// Description : LIN description file created by PREEvision
// Created : 4/22/24, 5:05 PM

LIN_description_file;
LIN_protocol_version = "2.2";
LIN_language_version = "2.2";
LIN_speed = 19.2 kbps;

Nodes {
  Master: BCM, 10 ms, 0.01 ms;
  Slaves: MCL, WLML, DIAG_TESTER_LIN1;
}

Signals {
  CapoteSts: 3, 0, BCM, WLML;
  BatteryVoltageLevel: 7, 0, BCM, WLML;
  Fdbk_Pos_Ver_LH_Exmi: 8, 255, MCL, BCM;
  Fdbk_Pos_Hor_LH_Exmi: 8, 255, MCL, BCM;
  Mem_Pos_Hor_Exmi: 8, 255, BCM, MCL;
  Mem_Pos_Ver_Exmi: 8, 255, BCM, MCL;
  Mem_Exmi_Selected: 2, 3, BCM, MCL;
  Err_Watchdog_Timer_LH: 2, 3, MCL, BCM;
  Err_Heater_short_Open_Circuit_LH: 2, 3, MCL, BCM;
  Err_ElectroChrom_short_Open_Circuit_LH: 2, 3, MCL, BCM;
  Err_Potentiometer_V_Value_LH: 2, 3, MCL, BCM;
  Err_Glass_Actuator_LH: 2, 3, MCL, BCM;
  Err_Puddle_Light_LH: 2, 3, MCL, BCM;
  ERR_ST_EXMI_LH_06_LIN: 2, 3, MCL, BCM;
  ERR_ST_EXMI_LH_07_LIN: 2, 3, MCL, BCM;
  ERR_ST_EXMI_LH_08_LIN: 2, 3, MCL, BCM;
  Err_Fold_Short_Open_Circuit_LH: 2, 3, MCL, BCM;
  ERR_ST_EXMI_LH_10_LIN: 2, 3, MCL, BCM;
  Err_Undervoltage_LH: 2, 3, MCL, BCM;
  Err_Overvoltage_LH: 2, 3, MCL, BCM;
  Err_Heater_Undervoltage_LH: 2, 3, MCL, BCM;
  Err_Over_Temp_microC_LH: 2, 3, MCL, BCM;
  ERR_ST_EXMI_LH_15_LIN: 2, 3, MCL, BCM;
  VRS_EXMI_LH_LIN: 8, 255, MCL, BCM;
  ST_DSE_1_LH_WARN_LNCH_LIN: 4, 15, MCL, BCM;
  NOD_ERR_EXMI_LH_LIN: 2, 3, MCL, BCM;
  COMM_ERR_EXMI_LH_LIN: 1, 0, MCL, BCM;
  Mirror_Selected: 2, 2, BCM, MCL;
  Mirror_Movement_Direction_Cmd: 4, 15, BCM, MCL;
  Mirror_Fold_Cmd: 2, 3, BCM, MCL;
  Mirror_Electrochromic_Dimming_Cmd: 8, 255, BCM, MCL;
  Mirror_Heater_Cmd: 3, 7, BCM, MCL;
  Puddle_Light_Dimming_Cmd: 8, 255, BCM, MCL;
  Puddle_Light_LH_Mode_Cmd: 4, 15, BCM, MCL;
  Puddle_Light_RH_Mode_Cmd: 4, 15, BCM, MCL;
  WLMLShortDrop: 1, 0, BCM, WLML;
  WLMLShortLift: 1, 0, BCM, WLML;
  WLM_ComfortClosing: 1, 0, BCM, WLML;
  CmdIgnSts: 3, 0, BCM, WLML;
  WLMRShortDrop: 1, 0, BCM, DIAG_TESTER_LIN1, WLML;
  WLMRShortLift: 1, 0, BCM, DIAG_TESTER_LIN1, WLML;
  Key_off_enabler: 1, 0, BCM, WLML;
  WLML_Movement_Command: 3, 0, BCM, WLML;
  WLMR_Movement_Command: 3, 0, BCM, DIAG_TESTER_LIN1, WLML;
  WLML_Position_Command: 4, 11, BCM, WLML;
  WLMR_Position_Command: 4, 11, BCM, DIAG_TESTER_LIN1, WLML;
  WLM_CapoteWindowsMovementCmd: 2, 0, BCM, WLML;
  AntipinchEnabler: 2, 0, BCM, WLML;
  WindowSts_WLML: 4, 0, WLML, BCM;
  Position_Fbk_WLML: 4, 0, WLML, BCM;
  ShortDropMode_Sts_WLML: 1, 0, WLML, BCM;
  InitializationSts_WLML: 1, 0, WLML, BCM;
  AssemblyModeSts_WLML: 1, 0, WLML, BCM;
  ThermalSts_WLML: 2, 0, WLML, BCM;
  VoltageOutOfRange_WLML: 1, 0, WLML, BCM;
  ResponseError_WLML: 1, 0, WLML, BCM;
  CurrentFail_WLML: 1, 0, WLML, BCM;
  GenericFail_WLML: 1, 0, WLML, BCM;
  HallSensorFail_WLML: 1, 0, WLML, BCM;
  AntiPinchFail_WLML: 1, 0, WLML, BCM;
  RelayFail_WLML: 1, 0, WLML, BCM;
  PositionFail_WLML: 1, 0, WLML, BCM;
  ShortDropSignalFail_WLML: 1, 0, WLML, BCM;
  STS_LH_DoorStatus: 2, 0, BCM, WLML;
  ExternalTemperature: 9, 170, BCM, WLML;
  AnticlatterSts_WLML: 2, 0, WLML, BCM;
  VehicleSpeedFailSts: 1, 0, BCM, WLML;
  ExternalTemperatureFailSts: 1, 0, BCM, WLML;
  VehicleSpeed: 13, 0, BCM, WLML;
}

Frames {
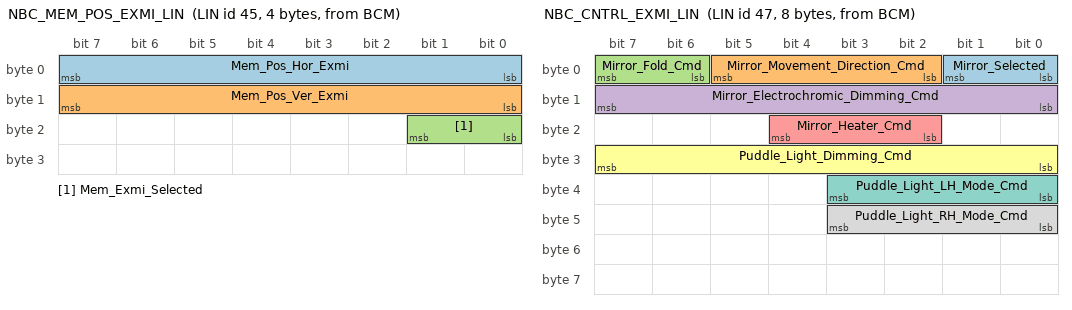
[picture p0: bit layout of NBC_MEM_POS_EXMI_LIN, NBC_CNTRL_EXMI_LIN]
  NBC_MEM_POS_EXMI_LIN: 45, BCM, 4 {
    Mem_Pos_Hor_Exmi, 0;
    Mem_Pos_Ver_Exmi, 8;
    Mem_Exmi_Selected, 16;
  }
  Fdbk_Pos_Exmi_LH: 17, MCL, 2 {
    Fdbk_Pos_Hor_LH_Exmi, 0;
    Fdbk_Pos_Ver_LH_Exmi, 8;
  }
  NBC_CNTRL_EXMI_LIN: 47, BCM, 8 {
    Mirror_Selected, 0;
    Mirror_Movement_Direction_Cmd, 2;
    Mirror_Fold_Cmd, 6;
    Mirror_Electrochromic_Dimming_Cmd, 8;
    Mirror_Heater_Cmd, 18;
    Puddle_Light_Dimming_Cmd, 24;
    Puddle_Light_LH_Mode_Cmd, 32;
    Puddle_Light_RH_Mode_Cmd, 40;
  }
  Err_LH_Exmi_Sts: 15, MCL, 8 {
    Err_Watchdog_Timer_LH, 0;
    Err_Heater_short_Open_Circuit_LH, 2;
    Err_ElectroChrom_short_Open_Circuit_LH, 4;
    Err_Potentiometer_V_Value_LH, 6;
    Err_Glass_Actuator_LH, 8;
    Err_Puddle_Light_LH, 10;
    ERR_ST_EXMI_LH_06_LIN, 12;
    ERR_ST_EXMI_LH_07_LIN, 14;
    ERR_ST_EXMI_LH_08_LIN, 16;
    Err_Fold_Short_Open_Circuit_LH, 18;
    ERR_ST_EXMI_LH_10_LIN, 20;
    Err_Undervoltage_LH, 22;
    Err_Overvoltage_LH, 24;
    Err_Heater_Undervoltage_LH, 26;
    Err_Over_Temp_microC_LH, 28;
    ERR_ST_EXMI_LH_15_LIN, 30;
    VRS_EXMI_LH_LIN, 32;
  }
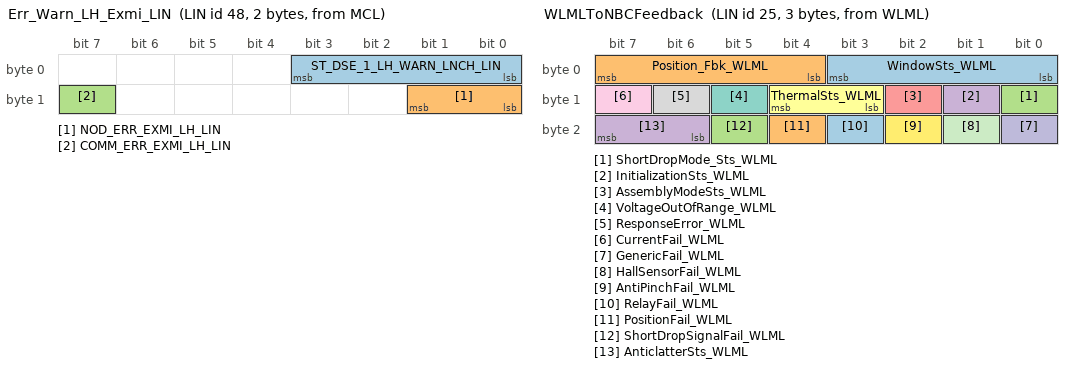
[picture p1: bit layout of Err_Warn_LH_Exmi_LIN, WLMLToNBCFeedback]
  Err_Warn_LH_Exmi_LIN: 48, MCL, 2 {
    ST_DSE_1_LH_WARN_LNCH_LIN, 0;
    NOD_ERR_EXMI_LH_LIN, 8;
    COMM_ERR_EXMI_LH_LIN, 15;
  }
  NBCToWLMCommand: 24, BCM, 8 {
    WLMLShortDrop, 7;
    WLMLShortLift, 8;
    WLM_ComfortClosing, 9;
    CmdIgnSts, 20;
    WLMRShortDrop, 23;
    WLMRShortLift, 24;
    Key_off_enabler, 25;
    WLML_Movement_Command, 26;
    WLMR_Movement_Command, 29;
    WLML_Position_Command, 46;
    WLMR_Position_Command, 50;
    WLM_CapoteWindowsMovementCmd, 54;
    AntipinchEnabler, 56;
    ExternalTemperature, 10;
    BatteryVoltageLevel, 0;
    STS_LH_DoorStatus, 61;
    CapoteSts, 58;
    ExternalTemperatureFailSts, 19;
    VehicleSpeedFailSts, 45;
    VehicleSpeed, 32;
  }
  WLMLToNBCFeedback: 25, WLML, 3 {
    WindowSts_WLML, 0;
    Position_Fbk_WLML, 4;
    ShortDropMode_Sts_WLML, 8;
    InitializationSts_WLML, 9;
    AssemblyModeSts_WLML, 10;
    ThermalSts_WLML, 11;
    VoltageOutOfRange_WLML, 13;
    ResponseError_WLML, 14;
    CurrentFail_WLML, 15;
    GenericFail_WLML, 16;
    HallSensorFail_WLML, 17;
    AntiPinchFail_WLML, 18;
    RelayFail_WLML, 19;
    PositionFail_WLML, 20;
    ShortDropSignalFail_WLML, 21;
    AnticlatterSts_WLML, 22;
  }
}

Node_attributes {
  MCL {
    LIN_protocol = "1.3";
    configured_NAD = 0x3;
  }
  WLML {
    LIN_protocol = "2.2";
    configured_NAD = 0x71;
    initial_NAD = 0x71;
    product_id = 0x0000, 0x0000, 0x00;
    response_error = ResponseError_WLML;
    P2_min = 50 ms;
    configurable_frames {
      NBCToWLMCommand;
      WLMLToNBCFeedback;
    }
  }
  DIAG_TESTER_LIN1 {
    LIN_protocol = "1.3";
    configured_NAD = 0x40;
  }
}

Schedule_tables {
  Init {
    SlaveResp delay 10 ms;
    MasterReq delay 10 ms;
  }
  MCL {
    NBC_MEM_POS_EXMI_LIN delay 10 ms;
    Fdbk_Pos_Exmi_LH delay 10 ms;
    Err_LH_Exmi_Sts delay 10 ms;
    NBC_CNTRL_EXMI_LIN delay 10 ms;
    Err_Warn_LH_Exmi_LIN delay 10 ms;
  }
  WLML_MCL {
    NBC_MEM_POS_EXMI_LIN delay 10 ms;
    Fdbk_Pos_Exmi_LH delay 10 ms;
    Err_LH_Exmi_Sts delay 10 ms;
    NBCToWLMCommand delay 10 ms;
    NBC_CNTRL_EXMI_LIN delay 10 ms;
    Err_Warn_LH_Exmi_LIN delay 10 ms;
    WLMLToNBCFeedback delay 10 ms;
  }
  WLML {
    NBCToWLMCommand delay 10 ms;
    WLMLToNBCFeedback delay 10 ms;
  }
}

Signal_encoding_types {
  Mem_Pos_Hor_Exmi_Encoding {
    logical_value, 255, "Invalid Signal";
    physical_value, 0, 255, 1, 0, "Position Value";
  }
  Mem_Pos_Ver_Exmi_Encoding {
    logical_value, 255, "Invalid Signal";
    physical_value, 0, 255, 1, 0, "Position Value";
  }
  Mem_Exmi_Selected_Encoding {
    logical_value, 0, "Left Mirror";
    logical_value, 1, "Right Mirror";
    logical_value, 2, "Not Used";
    logical_value, 3, "Invalid Signal";
  }
  Err_Watchdog_Timer_LH_Encoding {
    logical_value, 0, "No Failure";
    logical_value, 1, "Failure Active";
    logical_value, 2, "Not used";
    logical_value, 3, "Invalid Signal";
  }
  Err_Heater_short_Open_Circuit_LH_Encoding {
    logical_value, 0, "No Failure";
    logical_value, 1, "Failure Active";
    logical_value, 2, "Not used";
    logical_value, 3, "Invalid Signal";
  }
  Err_ElectroChrom_short_Open_Circuit_LH_Encoding {
    logical_value, 0, "No Failure";
    logical_value, 1, "Failure Active";
    logical_value, 2, "Not used";
    logical_value, 3, "Invalid Signal";
  }
  Err_Potentiometer_V_Value_LH_Encoding {
    logical_value, 0, "No Failure";
    logical_value, 1, "Failure Active";
    logical_value, 2, "Not used";
    logical_value, 3, "Invalid Signal";
  }
  Err_Glass_Actuator_LH_Encoding {
    logical_value, 0, "No Failure";
    logical_value, 1, "Failure Active";
    logical_value, 2, "Not used";
    logical_value, 3, "Invalid Signal";
  }
  Err_Puddle_Light_LH_Encoding {
    logical_value, 0, "No Failure";
    logical_value, 1, "Failure Active";
    logical_value, 2, "Not used";
    logical_value, 3, "Invalid Signal";
  }
  ERR_ST_EXMI_LH_06_LIN_Encoding {
    logical_value, 0, "No Failure";
    logical_value, 1, "Failure Active";
    logical_value, 2, "Not used";
    logical_value, 3, "Invalid Signal";
  }
  ERR_ST_EXMI_LH_07_LIN_Encoding {
    logical_value, 0, "No Failure";
    logical_value, 1, "Failure Active";
    logical_value, 2, "Not used";
    logical_value, 3, "Invalid Signal";
  }
  ERR_ST_EXMI_LH_08_LIN_Encoding {
    logical_value, 0, "No Failure";
    logical_value, 1, "Failure Active";
    logical_value, 2, "Not used";
    logical_value, 3, "Invalid Signal";
  }
  Err_Fold_Short_Open_Circuit_LH_Encoding {
    logical_value, 0, "No Failure";
    logical_value, 1, "Failure Active";
    logical_value, 2, "Not used";
    logical_value, 3, "Invalid Signal";
  }
  ERR_ST_EXMI_LH_10_LIN_Encoding {
    logical_value, 0, "No Failure";
    logical_value, 1, "Failure Active";
    logical_value, 2, "Not used";
    logical_value, 3, "Invalid Signal";
  }
  Err_Undervoltage_LH_Encoding {
    logical_value, 0, "No Failure";
    logical_value, 1, "Failure Active (<8,5V)";
    logical_value, 2, "Not used";
    logical_value, 3, "Invalid Signal";
  }
  Err_Overvoltage_LH_Encoding {
    logical_value, 0, "No Failure";
    logical_value, 1, "Failure Active (>16,5V)";
    logical_value, 2, "Not used";
    logical_value, 3, "Invalid Signal";
  }
  Err_Heater_Undervoltage_LH_Encoding {
    logical_value, 0, "No Failure";
    logical_value, 1, "Failure Active";
    logical_value, 2, "Not used";
    logical_value, 3, "Invalid Signal";
  }
  Err_Over_Temp_microC_LH_Encoding {
    logical_value, 0, "No Failure";
    logical_value, 1, "Failure Active";
    logical_value, 2, "Not used";
    logical_value, 3, "Invalid Signal";
  }
  ERR_ST_EXMI_LH_15_LIN_Encoding {
    logical_value, 0, "No Failure";
    logical_value, 1, "Failure Active";
    logical_value, 2, "Not used";
    logical_value, 3, "Invalid Signal";
  }
  VRS_EXMI_LH_LIN_Encoding {
    logical_value, 255, "Invalid Signal";
    physical_value, 0, 255, 1, 0, "Position Value";
  }
  ST_DSE_1_LH_WARN_LNCH_LIN_Encoding {
    logical_value, 0, "Anzeige Segment AUS";
    logical_value, 1, "Anzeige Segment AN, kein Blinken";
    logical_value, 2, "Anzeige Segment AN, Blinken Stufe 1";
    logical_value, 3, "Anzeige Segment AN, Blinken Stufe 2";
    logical_value, 4, "Anzeige Segment AN, Blinken Stufe 3";
    logical_value, 5, "Not used";
    logical_value, 6, "Not used";
    logical_value, 7, "Not used";
    logical_value, 8, "Not used";
    logical_value, 9, "Not used";
    logical_value, 10, "Not used";
    logical_value, 11, "Not used";
    logical_value, 12, "Not used";
    logical_value, 13, "Error";
    logical_value, 14, "Not used";
    logical_value, 15, "Invalid Signal";
    physical_value, 0, 15, 1, 0, "raw";
  }
  NOD_ERR_EXMI_LH_LIN_Encoding {
    logical_value, 0, "No Failure";
    logical_value, 1, "Failure Active";
    logical_value, 2, "Failure Status Changed";
    logical_value, 3, "Invalid Signal";
    physical_value, 0, 3, 1, 0, "raw";
  }
  COMM_ERR_EXMI_LH_LIN_Encoding {
    logical_value, 0, "No Failure";
    logical_value, 1, "Failure Active";
    physical_value, 0, 1, 1, 0, "raw";
  }
  Mirror_Selected_Encoding {
    logical_value, 0, "Left Mirror";
    logical_value, 1, "Right Mirror";
    logical_value, 2, "Both Mirrors";
    logical_value, 3, "Invalid Signal";
  }
  Mirror_Movement_Direction_Cmd_Encoding {
    logical_value, 0, "No Movement";
    logical_value, 1, "Move Left";
    logical_value, 2, "Move Right";
    logical_value, 3, "Not used";
    logical_value, 4, "Move UP";
    logical_value, 5, "Not used";
    logical_value, 6, "Not used";
    logical_value, 7, "Not used";
    logical_value, 8, "Move DOWN";
    logical_value, 9, "Not used";
    logical_value, 10, "Not used";
    logical_value, 11, "Not used";
    logical_value, 12, "Not used";
    logical_value, 13, "Not used";
    logical_value, 14, "Not used";
    logical_value, 15, "Invalid Signal";
  }
  Mirror_Fold_Cmd_Encoding {
    logical_value, 0, "No Movement";
    logical_value, 1, "Fold";
    logical_value, 2, "Unfold";
    logical_value, 3, "Invalid Signal";
  }
  Mirror_Electrochromic_Dimming_Cmd_Encoding {
    logical_value, 255, "Invalid Signal";
    physical_value, 0, 100, 1, 0, "Abblendegrad in %";
  }
  Mirror_Heater_Cmd_Encoding {
    logical_value, 0, "Heater Off";
    logical_value, 1, "Heater 25% Power ON";
    logical_value, 2, "Heater 50% Power ON";
    logical_value, 3, "Heater 75% Power ON";
    logical_value, 4, "Heater 100% Power ON";
    logical_value, 5, "Not used";
    logical_value, 6, "Not used";
    logical_value, 7, "Invalid Signal";
  }
  Puddle_Light_Dimming_Cmd_Encoding {
    logical_value, 255, "Invalid Signal";
    physical_value, 0, 254, 1, 0, "%";
  }
  Puddle_Light_LH_Mode_Cmd_Encoding {
    logical_value, 0, "Off";
    logical_value, 1, "Solid";
    logical_value, 2, "Flashing 1";
    logical_value, 3, "Flashing 2";
    logical_value, 4, "Flashing 3";
    logical_value, 5, "Not used";
    logical_value, 6, "Not used";
    logical_value, 7, "Not used";
    logical_value, 8, "Initialization";
    logical_value, 9, "Not used";
    logical_value, 10, "Not used";
    logical_value, 11, "Not used";
    logical_value, 12, "Not used";
    logical_value, 13, "Not used";
    logical_value, 14, "Not used";
    logical_value, 15, "Invalid Signal";
  }
  Puddle_Light_RH_Mode_Cmd_Encoding {
    logical_value, 0, "Off";
    logical_value, 1, "Solid";
    logical_value, 2, "Flashing 1";
    logical_value, 3, "Flashing 2";
    logical_value, 4, "Flashing 3";
    logical_value, 5, "Not used";
    logical_value, 6, "Not used";
    logical_value, 7, "Not used";
    logical_value, 8, "Initialization";
    logical_value, 9, "Not used";
    logical_value, 10, "Not used";
    logical_value, 11, "Not used";
    logical_value, 12, "Not used";
    logical_value, 13, "Not used";
    logical_value, 14, "Not used";
    logical_value, 15, "Invalid Signal";
  }
  WLMLShortDrop_Encoding {
    logical_value, 0, "Not Active";
    logical_value, 1, "Active";
  }
  WLMLShortLift_Encoding {
    logical_value, 0, "Not Active";
    logical_value, 1, "Active";
  }
  WLM_ComfortClosing_Encoding {
    logical_value, 0, "Not Active";
    logical_value, 1, "Active";
  }
  ExternalTemperatureFailSts_Encoding {
    logical_value, 0, "Fail_Not_Present";
    logical_value, 1, "Fail_Present";
  }
  CmdIgnSts_Encoding {
    logical_value, 0, "IGN_LK";
    logical_value, 1, "IGN_S&S";
    logical_value, 2, "NA";
    logical_value, 3, "NA";
    logical_value, 4, "RUN";
    logical_value, 5, "START";
    logical_value, 6, "NA";
    logical_value, 7, "SNA";
  }
  WLMRShortDrop_Encoding {
    logical_value, 0, "Not Active";
    logical_value, 1, "Active";
  }
  WLMRShortLift_Encoding {
    logical_value, 0, "Not Active";
    logical_value, 1, "Active";
  }
  Key_off_enabler_Encoding {
    logical_value, 0, "Not Active";
    logical_value, 1, "Active";
  }
  WLML_Movement_Command_Encoding {
    logical_value, 0, "No Command";
    logical_value, 1, "Up Manual";
    logical_value, 2, "Down Manual";
    logical_value, 3, "Up Auto";
    logical_value, 4, "Down Auto";
    logical_value, 5, "Stop Movement";
    logical_value, 6, "NA";
    logical_value, 7, "SNA";
  }
  WLMR_Movement_Command_Encoding {
    logical_value, 0, "No Command";
    logical_value, 1, "Up Manual";
    logical_value, 2, "Down Manual";
    logical_value, 3, "Up Auto";
    logical_value, 4, "Down Auto";
    logical_value, 5, "Stop Movement";
    logical_value, 6, "NA";
    logical_value, 7, "SNA";
  }
  VehicleSpeedFailSts_Encoding {
    logical_value, 0, "Fail_Not_Present";
    logical_value, 1, "Fail_Present";
  }
  WLML_Position_Command_Encoding {
    logical_value, 11, "No Command";
    logical_value, 12, "Service Position";
    logical_value, 13, "NA";
    logical_value, 14, "NA";
    logical_value, 15, "SNA";
    physical_value, 0, 10, 10, 0, "%";
  }
  WLMR_Position_Command_Encoding {
    logical_value, 11, "No Command";
    logical_value, 12, "Service Position";
    logical_value, 13, "NA";
    logical_value, 14, "NA";
    logical_value, 15, "SNA";
    physical_value, 0, 10, 10, 0, "%";
  }
  WLM_CapoteWindowsMovementCmd_Encoding {
    logical_value, 0, "No_Command";
    logical_value, 1, "Up_To_ShortDrop";
    logical_value, 2, "Up_Movement";
    logical_value, 3, "Down_Movement";
  }
  AntipinchEnabler_Encoding {
    logical_value, 0, "Not Enabled";
    logical_value, 1, "Enabled";
  }
  CapoteSts_Encoding {
    logical_value, 0, "Closed";
    logical_value, 1, "Opened";
    logical_value, 2, "Closing";
    logical_value, 3, "Opening";
    logical_value, 4, "Middle";
    logical_value, 5, "Not used";
    logical_value, 6, "Not used";
    logical_value, 7, "Capote not present";
  }
  WindowSts_WLML_Encoding {
    logical_value, 0, "Open";
    logical_value, 1, "Closed";
    logical_value, 2, "Stopped in intermediate position";
    logical_value, 3, "Running Up";
    logical_value, 4, "Running Down";
    logical_value, 5, "Reverse";
    logical_value, 6, "Short drop";
    logical_value, 7, "SNA";
    logical_value, 8, "Running Up Auto";
    logical_value, 9, "Running Down Auto";
    logical_value, 10, "Not Used";
    logical_value, 11, "Not Used";
    logical_value, 12, "Not Used";
    logical_value, 13, "Not Used";
    logical_value, 14, "Not Used";
    logical_value, 15, "Not Used";
  }
  Position_Fbk_WLML_Encoding {
    physical_value, 0, 100, 10, 0, "%";
  }
  ShortDropMode_Sts_WLML_Encoding {
    logical_value, 0, "Not Active";
    logical_value, 1, "Active";
  }
  InitializationSts_WLML_Encoding {
    logical_value, 0, "Not_Initialized";
    logical_value, 1, "Initialized";
  }
  AssemblyModeSts_WLML_Encoding {
    logical_value, 0, "Not Active";
    logical_value, 1, "Active";
  }
  ThermalSts_WLML_Encoding {
    logical_value, 0, "Normal Operation";
    logical_value, 1, "State_1";
    logical_value, 2, "State_2";
    logical_value, 3, "SNA";
  }
  VoltageOutOfRange_WLML_Encoding {
    logical_value, 0, "Fail_Not_Present";
    logical_value, 1, "Fail_Present";
  }
  ResponseError_WLML_Encoding {
    logical_value, 0, "Fail_Not_Present";
    logical_value, 1, "Fail_Present";
  }
  CurrentFail_WLML_Encoding {
    logical_value, 0, "Fail_Not_Present";
    logical_value, 1, "Fail_Present";
  }
  GenericFail_WLML_Encoding {
    logical_value, 0, "Fail_Not_Present";
    logical_value, 1, "Fail_Present";
  }
  HallSensorFail_WLML_Encoding {
    logical_value, 0, "Fail_Not_Present";
    logical_value, 1, "Fail_Present";
  }
  AntiPinchFail_WLML_Encoding {
    logical_value, 0, "Fail_Not_Present";
    logical_value, 1, "Fail_Present";
  }
  RelayFail_WLML_Encoding {
    logical_value, 0, "Fail_Not_Present";
    logical_value, 1, "Fail_Present";
  }
  PositionFail_WLML_Encoding {
    logical_value, 0, "Fail_Not_Present";
    logical_value, 1, "Fail_Present";
  }
  ShortDropSignalFail_WLML_Encoding {
    logical_value, 0, "Fail_Not_Present";
    logical_value, 1, "Fail_Present";
  }
  STS_LH_DoorStatus_Encoding {
    logical_value, 0, "SNA";
    logical_value, 1, "Opened";
    logical_value, 2, "Ajar";
    logical_value, 3, "Closed";
  }
  AnticlatterSts_WLML_Encoding {
    logical_value, 0, "Out Of Anticlatter";
    logical_value, 1, "Running Anticlatter";
    logical_value, 2, "Anticlatter Position";
    logical_value, 3, "Anticlatter Not Active";
  }
  ExternalTemperature {
    physical_value, 0, 511, 0.5, -85, "°C";
  }
  std_q1p0_oq0p0_s8 {
    physical_value, 0, 255, 1, 0, "";
  }
  Fdbk_Pos_Hor_LH_Exmi {
    logical_value, 255, "Invalid_Signal";
    physical_value, 0, 255, 1, 0, "Position Value";
  }
  Fdbk_Pos_Ver_LH_Exmi {
    logical_value, 255, "Invalid_Signal";
    physical_value, 0, 255, 1, 0, "Position Value";
  }
  BatteryVoltageLevel {
    physical_value, 0, 127, 0.16, 0, "volt";
  }
  VehicleSpeedVSOSig8191 {
    physical_value, 0, 8191, 0.0625, 0, "km/h";
  }
}

Signal_representation {
  AntiPinchFail_WLML_Encoding: AntiPinchFail_WLML;
  AnticlatterSts_WLML_Encoding: AnticlatterSts_WLML;
  AntipinchEnabler_Encoding: AntipinchEnabler;
  AssemblyModeSts_WLML_Encoding: AssemblyModeSts_WLML;
  BatteryVoltageLevel: BatteryVoltageLevel;
  COMM_ERR_EXMI_LH_LIN_Encoding: COMM_ERR_EXMI_LH_LIN;
  CapoteSts_Encoding: CapoteSts;
  CmdIgnSts_Encoding: CmdIgnSts;
  CurrentFail_WLML_Encoding: CurrentFail_WLML;
  ERR_ST_EXMI_LH_06_LIN_Encoding: ERR_ST_EXMI_LH_06_LIN;
  ERR_ST_EXMI_LH_07_LIN_Encoding: ERR_ST_EXMI_LH_07_LIN;
  ERR_ST_EXMI_LH_08_LIN_Encoding: ERR_ST_EXMI_LH_08_LIN;
  ERR_ST_EXMI_LH_10_LIN_Encoding: ERR_ST_EXMI_LH_10_LIN;
  ERR_ST_EXMI_LH_15_LIN_Encoding: ERR_ST_EXMI_LH_15_LIN;
  Err_ElectroChrom_short_Open_Circuit_LH_Encoding: Err_ElectroChrom_short_Open_Circuit_LH;
  Err_Fold_Short_Open_Circuit_LH_Encoding: Err_Fold_Short_Open_Circuit_LH;
  Err_Glass_Actuator_LH_Encoding: Err_Glass_Actuator_LH;
  Err_Heater_Undervoltage_LH_Encoding: Err_Heater_Undervoltage_LH;
  Err_Heater_short_Open_Circuit_LH_Encoding: Err_Heater_short_Open_Circuit_LH;
  Err_Over_Temp_microC_LH_Encoding: Err_Over_Temp_microC_LH;
  Err_Overvoltage_LH_Encoding: Err_Overvoltage_LH;
  Err_Potentiometer_V_Value_LH_Encoding: Err_Potentiometer_V_Value_LH;
  Err_Puddle_Light_LH_Encoding: Err_Puddle_Light_LH;
  Err_Undervoltage_LH_Encoding: Err_Undervoltage_LH;
  Err_Watchdog_Timer_LH_Encoding: Err_Watchdog_Timer_LH;
  ExternalTemperature: ExternalTemperature;
  ExternalTemperatureFailSts_Encoding: ExternalTemperatureFailSts;
  Fdbk_Pos_Hor_LH_Exmi: Fdbk_Pos_Hor_LH_Exmi;
  Fdbk_Pos_Ver_LH_Exmi: Fdbk_Pos_Ver_LH_Exmi;
  GenericFail_WLML_Encoding: GenericFail_WLML;
  HallSensorFail_WLML_Encoding: HallSensorFail_WLML;
  InitializationSts_WLML_Encoding: InitializationSts_WLML;
  Key_off_enabler_Encoding: Key_off_enabler;
  Mem_Exmi_Selected_Encoding: Mem_Exmi_Selected;
  Mem_Pos_Hor_Exmi_Encoding: Mem_Pos_Hor_Exmi;
  Mem_Pos_Ver_Exmi_Encoding: Mem_Pos_Ver_Exmi;
  Mirror_Electrochromic_Dimming_Cmd_Encoding: Mirror_Electrochromic_Dimming_Cmd;
  Mirror_Fold_Cmd_Encoding: Mirror_Fold_Cmd;
  Mirror_Heater_Cmd_Encoding: Mirror_Heater_Cmd;
  Mirror_Movement_Direction_Cmd_Encoding: Mirror_Movement_Direction_Cmd;
  Mirror_Selected_Encoding: Mirror_Selected;
  NOD_ERR_EXMI_LH_LIN_Encoding: NOD_ERR_EXMI_LH_LIN;
  PositionFail_WLML_Encoding: PositionFail_WLML;
  Position_Fbk_WLML_Encoding: Position_Fbk_WLML;
  Puddle_Light_Dimming_Cmd_Encoding: Puddle_Light_Dimming_Cmd;
  Puddle_Light_LH_Mode_Cmd_Encoding: Puddle_Light_LH_Mode_Cmd;
  Puddle_Light_RH_Mode_Cmd_Encoding: Puddle_Light_RH_Mode_Cmd;
  RelayFail_WLML_Encoding: RelayFail_WLML;
  ResponseError_WLML_Encoding: ResponseError_WLML;
  STS_LH_DoorStatus_Encoding: STS_LH_DoorStatus;
  ST_DSE_1_LH_WARN_LNCH_LIN_Encoding: ST_DSE_1_LH_WARN_LNCH_LIN;
  ShortDropMode_Sts_WLML_Encoding: ShortDropMode_Sts_WLML;
  ShortDropSignalFail_WLML_Encoding: ShortDropSignalFail_WLML;
  ThermalSts_WLML_Encoding: ThermalSts_WLML;
  VRS_EXMI_LH_LIN_Encoding: VRS_EXMI_LH_LIN;
  VehicleSpeedFailSts_Encoding: VehicleSpeedFailSts;
  VehicleSpeedVSOSig8191: VehicleSpeed;
  VoltageOutOfRange_WLML_Encoding: VoltageOutOfRange_WLML;
  WLMLShortDrop_Encoding: WLMLShortDrop;
  WLMLShortLift_Encoding: WLMLShortLift;
  WLML_Movement_Command_Encoding: WLML_Movement_Command;
  WLML_Position_Command_Encoding: WLML_Position_Command;
  WLMRShortDrop_Encoding: WLMRShortDrop;
  WLMRShortLift_Encoding: WLMRShortLift;
  WLMR_Movement_Command_Encoding: WLMR_Movement_Command;
  WLMR_Position_Command_Encoding: WLMR_Position_Command;
  WLM_CapoteWindowsMovementCmd_Encoding: WLM_CapoteWindowsMovementCmd;
  WLM_ComfortClosing_Encoding: WLM_ComfortClosing;
  WindowSts_WLML_Encoding: WindowSts_WLML;
  std_q1p0_oq0p0_s8: MasterReqB0, MasterReqB1, MasterReqB2, MasterReqB3, MasterReqB4, MasterReqB5, MasterReqB6, MasterReqB7, SlaveRespB0, SlaveRespB1, SlaveRespB2, SlaveRespB3, SlaveRespB4, SlaveRespB5, SlaveRespB6, SlaveRespB7;
}
